VERSION ""

NS_ :

BS_:

BU_:
VAL_TABLE_ TS_states 3 "Error" 2 "Operate" 1 "Pre-charging" 0 "Standby" ;
VAL_TABLE_ validity 1 "true" 0 "false" ;
VAL_TABLE_ ValueStatus 3 "Invalid - Open sensor wire" 2 "Invalid - Value out of range" 1 "Invalid - PEC error" 0 "Valid" ;
VAL_TABLE_ States 1 "Active" 0 "Inactive" ;
VAL_TABLE_ SlaveMultiplex 11 "Slave 12" 10 "Slave 11" 9 "Slave 10" 8 "Slave 9" 7 "Slave 8" 6 "Slave 7" 5 "Slave 6" 4 "Slave 5" 3 "Slave 4" 2 "Slave 3" 1 "Slave 2" 0 "Slave 1" ;

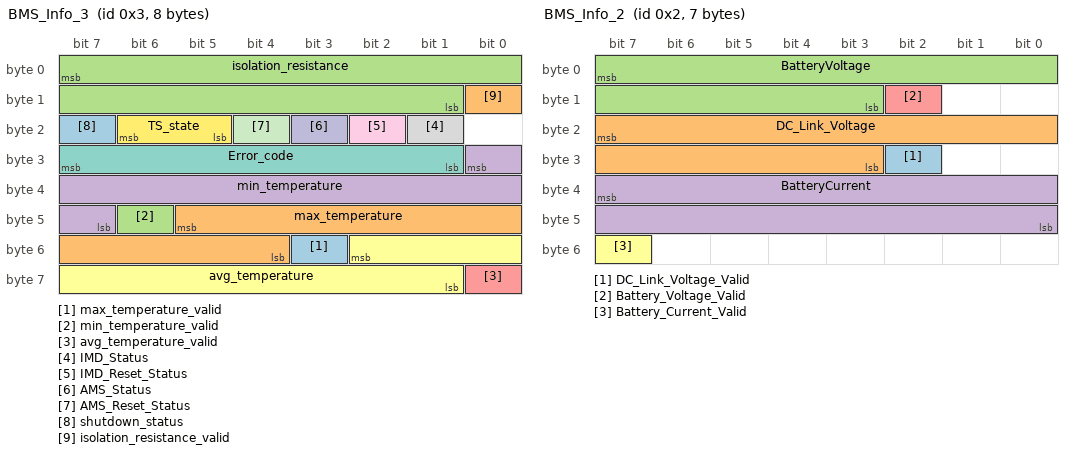
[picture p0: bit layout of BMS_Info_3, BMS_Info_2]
BO_ 3 BMS_Info_3: 8 Vector__XXX
 SG_ max_temperature_valid : 51|1@0+ (1,0) [0|0] "" Vector__XXX
 SG_ max_temperature : 45|10@0+ (0.1,0) [0|102.3] "°C" Vector__XXX
 SG_ min_temperature_valid : 46|1@0+ (1,0) [0|0] "" Vector__XXX
 SG_ min_temperature : 24|10@0+ (0.1,0) [0|102.3] "°C" Vector__XXX
 SG_ avg_temperature_valid : 56|1@0+ (1,0) [0|0] "" Vector__XXX
 SG_ avg_temperature : 50|10@0+ (0.1,0) [0|102.3] "°C" Vector__XXX
 SG_ Error_code : 31|7@0+ (1,0) [0|0] "" Vector__XXX
 SG_ IMD_Status : 17|1@0+ (1,0) [0|0] "" Vector__XXX
 SG_ IMD_Reset_Status : 18|1@0+ (1,0) [0|0] "" Vector__XXX
 SG_ AMS_Status : 19|1@0+ (1,0) [0|0] "" Vector__XXX
 SG_ AMS_Reset_Status : 20|1@0+ (1,0) [0|0] "" Vector__XXX
 SG_ TS_state : 22|2@0+ (1,0) [0|0] "" Vector__XXX
 SG_ shutdown_status : 23|1@0+ (1,0) [0|0] "" Vector__XXX
 SG_ isolation_resistance_valid : 8|1@0+ (1,0) [0|0] "" Vector__XXX
 SG_ isolation_resistance : 7|15@0+ (0.1,0) [0|3276.7] "kOhm" Vector__XXX

BO_ 2 BMS_Info_2: 7 Vector__XXX
 SG_ DC_Link_Voltage_Valid : 26|1@0+ (1,0) [0|0] "" Vector__XXX
 SG_ DC_Link_Voltage : 23|13@0+ (0.1,0) [0|819.1] "V" Vector__XXX
 SG_ BatteryVoltage : 7|13@0+ (0.1,0) [0|819.1] "V" Vector__XXX
 SG_ BatteryCurrent : 39|16@0- (0.00625,0) [-200|200] "A" Vector__XXX
 SG_ Battery_Voltage_Valid : 10|1@0+ (1,0) [0|0] "" Vector__XXX
 SG_ Battery_Current_Valid : 55|1@0+ (1,0) [0|0] "" Vector__XXX

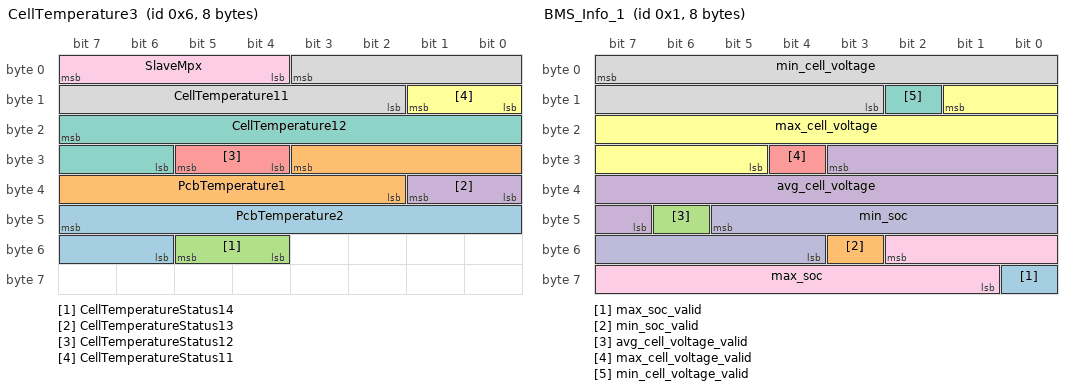
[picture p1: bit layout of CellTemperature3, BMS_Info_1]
BO_ 6 CellTemperature3: 8 Vector__XXX
 SG_ PcbTemperature2 : 47|10@0+ (0.1,0) [0|102.3] "°C" Vector__XXX
 SG_ PcbTemperature1 : 27|10@0+ (0.1,0) [0|102.3] "°C" Vector__XXX
 SG_ CellTemperatureStatus14 : 53|2@0+ (1,0) [0|3] "" Vector__XXX
 SG_ CellTemperatureStatus13 : 33|2@0+ (1,0) [0|3] "" Vector__XXX
 SG_ CellTemperatureStatus12 : 29|2@0+ (1,0) [0|3] "" Vector__XXX
 SG_ CellTemperatureStatus11 : 9|2@0+ (1,0) [0|3] "" Vector__XXX
 SG_ CellTemperature12 : 23|10@0+ (0.1,0) [0|102.3] "°C" Vector__XXX
 SG_ CellTemperature11 : 3|10@0+ (0.1,0) [0|102.3] "°C" Vector__XXX
 SG_ SlaveMpx : 7|4@0+ (1,0) [0|11] "" Vector__XXX

BO_ 1 BMS_Info_1: 8 Vector__XXX
 SG_ max_soc_valid : 56|1@0+ (1,0) [0|0] "" Vector__XXX
 SG_ min_soc_valid : 51|1@0+ (1,0) [0|0] "" Vector__XXX
 SG_ avg_cell_voltage_valid : 46|1@0+ (1,0) [0|0] "" Vector__XXX
 SG_ avg_cell_voltage : 27|13@0+ (0.001,0) [0|8.191] "V" Vector__XXX
 SG_ max_cell_voltage_valid : 28|1@0+ (1,0) [0|0] "" Vector__XXX
 SG_ max_cell_voltage : 9|13@0+ (0.001,0) [0|8.191] "V" Vector__XXX
 SG_ min_cell_voltage_valid : 10|1@0+ (1,0) [0|0] "" Vector__XXX
 SG_ min_cell_voltage : 7|13@0+ (0.001,0) [0|8.191] "V" Vector__XXX
 SG_ max_soc : 50|10@0+ (0.1,0) [0|100] "%" Vector__XXX
 SG_ min_soc : 45|10@0+ (0.1,0) [0|100] "%" Vector__XXX

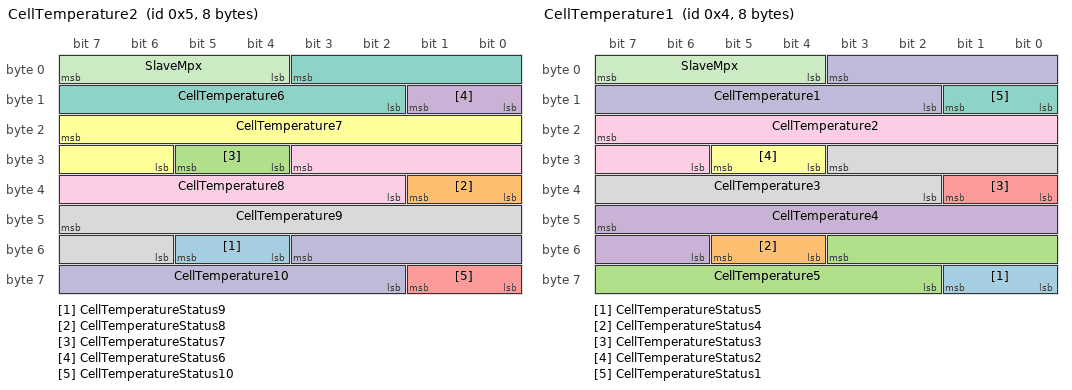
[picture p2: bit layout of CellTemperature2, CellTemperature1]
BO_ 5 CellTemperature2: 8 Vector__XXX
 SG_ CellTemperatureStatus9 : 53|2@0+ (1,0) [0|3] "" Vector__XXX
 SG_ CellTemperatureStatus8 : 33|2@0+ (1,0) [0|3] "" Vector__XXX
 SG_ CellTemperatureStatus7 : 29|2@0+ (1,0) [0|3] "" Vector__XXX
 SG_ CellTemperatureStatus6 : 9|2@0+ (1,0) [0|3] "" Vector__XXX
 SG_ CellTemperatureStatus10 : 57|2@0+ (1,0) [0|3] "" Vector__XXX
 SG_ CellTemperature7 : 23|10@0+ (0.1,0) [0|102.3] "°C" Vector__XXX
 SG_ CellTemperature6 : 3|10@0+ (0.1,0) [0|102.3] "°C" Vector__XXX
 SG_ CellTemperature9 : 47|10@0+ (0.1,0) [0|102.3] "°C" Vector__XXX
 SG_ CellTemperature8 : 27|10@0+ (0.1,0) [0|102.3] "°C" Vector__XXX
 SG_ CellTemperature10 : 51|10@0+ (0.1,0) [0|102.3] "°C" Vector__XXX
 SG_ SlaveMpx : 7|4@0+ (1,0) [0|11] "" Vector__XXX

BO_ 4 CellTemperature1: 8 Vector__XXX
 SG_ CellTemperatureStatus5 : 57|2@0+ (1,0) [0|3] "" Vector__XXX
 SG_ CellTemperatureStatus4 : 53|2@0+ (1,0) [0|3] "" Vector__XXX
 SG_ CellTemperature5 : 51|10@0+ (0.1,0) [0|102.3] "°C" Vector__XXX
 SG_ CellTemperature4 : 47|10@0+ (0.1,0) [0|102.3] "°C" Vector__XXX
 SG_ CellTemperatureStatus3 : 33|2@0+ (1,0) [0|3] "" Vector__XXX
 SG_ CellTemperatureStatus2 : 29|2@0+ (1,0) [0|3] "" Vector__XXX
 SG_ CellTemperatureStatus1 : 9|2@0+ (1,0) [0|3] "" Vector__XXX
 SG_ CellTemperature3 : 27|10@0+ (0.1,0) [0|102.3] "°C" Vector__XXX
 SG_ CellTemperature2 : 23|10@0+ (0.1,0) [0|102.3] "°C" Vector__XXX
 SG_ CellTemperature1 : 3|10@0+ (0.1,0) [0|102.3] "°C" Vector__XXX
 SG_ SlaveMpx : 7|4@0+ (1,0) [0|11] "" Vector__XXX

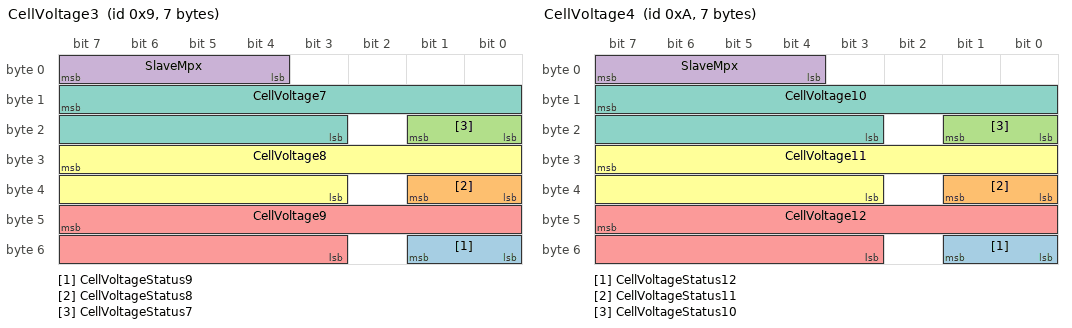
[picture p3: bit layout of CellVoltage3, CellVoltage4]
BO_ 9 CellVoltage3: 7 Vector__XXX
 SG_ CellVoltageStatus9 : 49|2@0+ (1,0) [0|3] "" Vector__XXX
 SG_ CellVoltageStatus8 : 33|2@0+ (1,0) [0|3] "" Vector__XXX
 SG_ CellVoltageStatus7 : 17|2@0+ (1,0) [0|3] "" Vector__XXX
 SG_ SlaveMpx : 7|4@0+ (1,0) [0|11] "" Vector__XXX
 SG_ CellVoltage9 : 47|13@0+ (0.001,0) [0|8.191] "V" Vector__XXX
 SG_ CellVoltage8 : 31|13@0+ (0.001,0) [0|8.191] "V" Vector__XXX
 SG_ CellVoltage7 : 15|13@0+ (0.001,0) [0|8.191] "V" Vector__XXX

BO_ 10 CellVoltage4: 7 Vector__XXX
 SG_ CellVoltageStatus12 : 49|2@0+ (1,0) [0|3] "" Vector__XXX
 SG_ CellVoltageStatus11 : 33|2@0+ (1,0) [0|3] "" Vector__XXX
 SG_ CellVoltageStatus10 : 17|2@0+ (1,0) [0|3] "" Vector__XXX
 SG_ SlaveMpx : 7|4@0+ (1,0) [0|11] "" Vector__XXX
 SG_ CellVoltage12 : 47|13@0+ (0.001,0) [0|8.191] "V" Vector__XXX
 SG_ CellVoltage11 : 31|13@0+ (0.001,0) [0|8.191] "V" Vector__XXX
 SG_ CellVoltage10 : 15|13@0+ (0.001,0) [0|8.191] "V" Vector__XXX

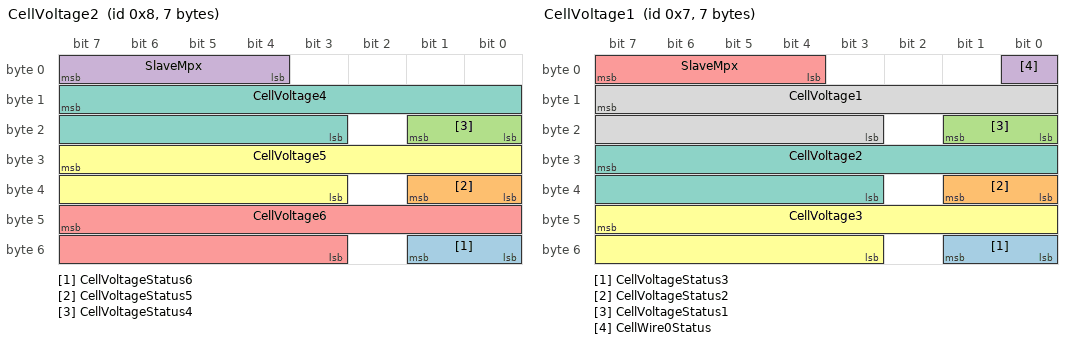
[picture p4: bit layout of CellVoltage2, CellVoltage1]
BO_ 8 CellVoltage2: 7 Vector__XXX
 SG_ CellVoltageStatus6 : 49|2@0+ (1,0) [0|3] "" Vector__XXX
 SG_ CellVoltageStatus5 : 33|2@0+ (1,0) [0|3] "" Vector__XXX
 SG_ CellVoltageStatus4 : 17|2@0+ (1,0) [0|3] "" Vector__XXX
 SG_ SlaveMpx : 7|4@0+ (1,0) [0|11] "" Vector__XXX
 SG_ CellVoltage6 : 47|13@0+ (0.001,0) [0|8.191] "V" Vector__XXX
 SG_ CellVoltage5 : 31|13@0+ (0.001,0) [0|8.191] "V" Vector__XXX
 SG_ CellVoltage4 : 15|13@0+ (0.001,0) [0|8.191] "V" Vector__XXX

BO_ 7 CellVoltage1: 7 Vector__XXX
 SG_ CellVoltageStatus3 : 49|2@0+ (1,0) [0|3] "" Vector__XXX
 SG_ CellVoltageStatus2 : 33|2@0+ (1,0) [0|3] "" Vector__XXX
 SG_ CellVoltageStatus1 : 17|2@0+ (1,0) [0|3] "" Vector__XXX
 SG_ CellWire0Status : 0|1@1- (1,0) [0|0] "" Vector__XXX
 SG_ SlaveMpx : 7|4@0+ (1,0) [0|11] "" Vector__XXX
 SG_ CellVoltage3 : 47|13@0+ (0.001,0) [0|8.191] "V" Vector__XXX
 SG_ CellVoltage2 : 31|13@0+ (0.001,0) [0|8.191] "V" Vector__XXX
 SG_ CellVoltage1 : 15|13@0+ (0.001,0) [0|8.191] "V" Vector__XXX

BO_ 11 UniqueID: 5 Vector__XXX
 SG_ SlaveMpx : 7|4@0+ (1,0) [0|11] "" Vector__XXX
 SG_ UID : 15|32@0+ (1,0) [0|4294967295] "" Vector__XXX

CM_ SG_ 7 CellWire0Status "0x0 = OK
0x1 = Open";
CM_ SG_ 11 UID "32 Bit unique ID";
BA_DEF_  "BusType" STRING ;
BA_DEF_DEF_  "BusType" "CAN";
VAL_ 3 max_temperature_valid 1 "true" 0 "false" ;
VAL_ 3 min_temperature_valid 1 "true" 0 "false" ;
VAL_ 3 avg_temperature_valid 1 "true" 0 "false" ;
VAL_ 3 IMD_Status 1 "Active" 0 "Inactive" ;
VAL_ 3 IMD_Reset_Status 1 "Active" 0 "Inactive" ;
VAL_ 3 AMS_Status 1 "Active" 0 "Inactive" ;
VAL_ 3 AMS_Reset_Status 1 "Active" 0 "Inactive" ;
VAL_ 3 TS_state 3 "Error" 2 "Operate" 1 "Pre-charging" 0 "Standby" ;
VAL_ 3 shutdown_status 1 "Active" 0 "Inactive" ;
VAL_ 3 isolation_resistance_valid 1 "true" 0 "false" ;
VAL_ 2 DC_Link_Voltage_Valid 1 "true" 0 "false" ;
VAL_ 2 Battery_Voltage_Valid 1 "true" 0 "false" ;
VAL_ 2 Battery_Current_Valid 1 "true" 0 "false" ;
VAL_ 6 CellTemperatureStatus14 3 "Invalid - Open sensor wire" 2 "Invalid - Value out of range" 1 "Invalid - PEC error" 0 "Valid" ;
VAL_ 6 CellTemperatureStatus13 3 "Invalid - Open sensor wire" 2 "Invalid - Value out of range" 1 "Invalid - PEC error" 0 "Valid" ;
VAL_ 6 CellTemperatureStatus12 3 "Invalid - Open sensor wire" 2 "Invalid - Value out of range" 1 "Invalid - PEC error" 0 "Valid" ;
VAL_ 6 CellTemperatureStatus11 3 "Invalid - Open sensor wire" 2 "Invalid - Value out of range" 1 "Invalid - PEC error" 0 "Valid" ;
VAL_ 6 SlaveMpx 11 "Slave 12" 10 "Slave 11" 9 "Slave 10" 8 "Slave 9" 7 "Slave 8" 6 "Slave 7" 5 "Slave 6" 4 "Slave 5" 3 "Slave 4" 2 "Slave 3" 1 "Slave 2" 0 "Slave 1" ;
VAL_ 1 max_soc_valid 1 "true" 0 "false" ;
VAL_ 1 min_soc_valid 1 "true" 0 "false" ;
VAL_ 1 avg_cell_voltage_valid 1 "true" 0 "false" ;
VAL_ 1 max_cell_voltage_valid 1 "true" 0 "false" ;
VAL_ 1 min_cell_voltage_valid 1 "true" 0 "false" ;
VAL_ 5 CellTemperatureStatus9 3 "Invalid - Open sensor wire" 2 "Invalid - Value out of range" 1 "Invalid - PEC error" 0 "Valid" ;
VAL_ 5 CellTemperatureStatus8 3 "Invalid - Open sensor wire" 2 "Invalid - Value out of range" 1 "Invalid - PEC error" 0 "Valid" ;
VAL_ 5 CellTemperatureStatus7 3 "Invalid - Open sensor wire" 2 "Invalid - Value out of range" 1 "Invalid - PEC error" 0 "Valid" ;
VAL_ 5 CellTemperatureStatus6 3 "Invalid - Open sensor wire" 2 "Invalid - Value out of range" 1 "Invalid - PEC error" 0 "Valid" ;
VAL_ 5 CellTemperatureStatus10 3 "Invalid - Open sensor wire" 2 "Invalid - Value out of range" 1 "Invalid - PEC error" 0 "Valid" ;
VAL_ 5 SlaveMpx 11 "Slave 12" 10 "Slave 11" 9 "Slave 10" 8 "Slave 9" 7 "Slave 8" 6 "Slave 7" 5 "Slave 6" 4 "Slave 5" 3 "Slave 4" 2 "Slave 3" 1 "Slave 2" 0 "Slave 1" ;
VAL_ 4 CellTemperatureStatus5 3 "Invalid - Open sensor wire" 2 "Invalid - Value out of range" 1 "Invalid - PEC error" 0 "Valid" ;
VAL_ 4 CellTemperatureStatus4 3 "Invalid - Open sensor wire" 2 "Invalid - Value out of range" 1 "Invalid - PEC error" 0 "Valid" ;
VAL_ 4 CellTemperatureStatus3 3 "Invalid - Open sensor wire" 2 "Invalid - Value out of range" 1 "Invalid - PEC error" 0 "Valid" ;
VAL_ 4 CellTemperatureStatus2 3 "Invalid - Open sensor wire" 2 "Invalid - Value out of range" 1 "Invalid - PEC error" 0 "Valid" ;
VAL_ 4 CellTemperatureStatus1 3 "Invalid - Open sensor wire" 2 "Invalid - Value out of range" 1 "Invalid - PEC error" 0 "Valid" ;
VAL_ 4 SlaveMpx 11 "Slave 12" 10 "Slave 11" 9 "Slave 10" 8 "Slave 9" 7 "Slave 8" 6 "Slave 7" 5 "Slave 6" 4 "Slave 5" 3 "Slave 4" 2 "Slave 3" 1 "Slave 2" 0 "Slave 1" ;
VAL_ 9 CellVoltageStatus9 3 "Invalid - Open sensor wire" 2 "Invalid - Value out of range" 1 "Invalid - PEC error" 0 "Valid" ;
VAL_ 9 CellVoltageStatus8 3 "Invalid - Open sensor wire" 2 "Invalid - Value out of range" 1 "Invalid - PEC error" 0 "Valid" ;
VAL_ 9 CellVoltageStatus7 3 "Invalid - Open sensor wire" 2 "Invalid - Value out of range" 1 "Invalid - PEC error" 0 "Valid" ;
VAL_ 9 SlaveMpx 11 "Slave 12" 10 "Slave 11" 9 "Slave 10" 8 "Slave 9" 7 "Slave 8" 6 "Slave 7" 5 "Slave 6" 4 "Slave 5" 3 "Slave 4" 2 "Slave 3" 1 "Slave 2" 0 "Slave 1" ;
VAL_ 10 CellVoltageStatus12 3 "Invalid - Open sensor wire" 2 "Invalid - Value out of range" 1 "Invalid - PEC error" 0 "Valid" ;
VAL_ 10 CellVoltageStatus11 3 "Invalid - Open sensor wire" 2 "Invalid - Value out of range" 1 "Invalid - PEC error" 0 "Valid" ;
VAL_ 10 CellVoltageStatus10 3 "Invalid - Open sensor wire" 2 "Invalid - Value out of range" 1 "Invalid - PEC error" 0 "Valid" ;
VAL_ 10 SlaveMpx 11 "Slave 12" 10 "Slave 11" 9 "Slave 10" 8 "Slave 9" 7 "Slave 8" 6 "Slave 7" 5 "Slave 6" 4 "Slave 5" 3 "Slave 4" 2 "Slave 3" 1 "Slave 2" 0 "Slave 1" ;
VAL_ 8 CellVoltageStatus6 3 "Invalid - Open sensor wire" 2 "Invalid - Value out of range" 1 "Invalid - PEC error" 0 "Valid" ;
VAL_ 8 CellVoltageStatus5 3 "Invalid - Open sensor wire" 2 "Invalid - Value out of range" 1 "Invalid - PEC error" 0 "Valid" ;
VAL_ 8 CellVoltageStatus4 3 "Invalid - Open sensor wire" 2 "Invalid - Value out of range" 1 "Invalid - PEC error" 0 "Valid" ;
VAL_ 8 SlaveMpx 11 "Slave 12" 10 "Slave 11" 9 "Slave 10" 8 "Slave 9" 7 "Slave 8" 6 "Slave 7" 5 "Slave 6" 4 "Slave 5" 3 "Slave 4" 2 "Slave 3" 1 "Slave 2" 0 "Slave 1" ;
VAL_ 7 CellVoltageStatus3 3 "Invalid - Open sensor wire" 2 "Invalid - Value out of range" 1 "Invalid - PEC error" 0 "Valid" ;
VAL_ 7 CellVoltageStatus2 3 "Invalid - Open sensor wire" 2 "Invalid - Value out of range" 1 "Invalid - PEC error" 0 "Valid" ;
VAL_ 7 CellVoltageStatus1 3 "Invalid - Open sensor wire" 2 "Invalid - Value out of range" 1 "Invalid - PEC error" 0 "Valid" ;
VAL_ 7 SlaveMpx 11 "Slave 12" 10 "Slave 11" 9 "Slave 10" 8 "Slave 9" 7 "Slave 8" 6 "Slave 7" 5 "Slave 6" 4 "Slave 5" 3 "Slave 4" 2 "Slave 3" 1 "Slave 2" 0 "Slave 1" ;
VAL_ 11 SlaveMpx 11 "Slave 12" 10 "Slave 11" 9 "Slave 10" 8 "Slave 9" 7 "Slave 8" 6 "Slave 7" 5 "Slave 6" 4 "Slave 5" 3 "Slave 4" 2 "Slave 3" 1 "Slave 2" 0 "Slave 1" ;
